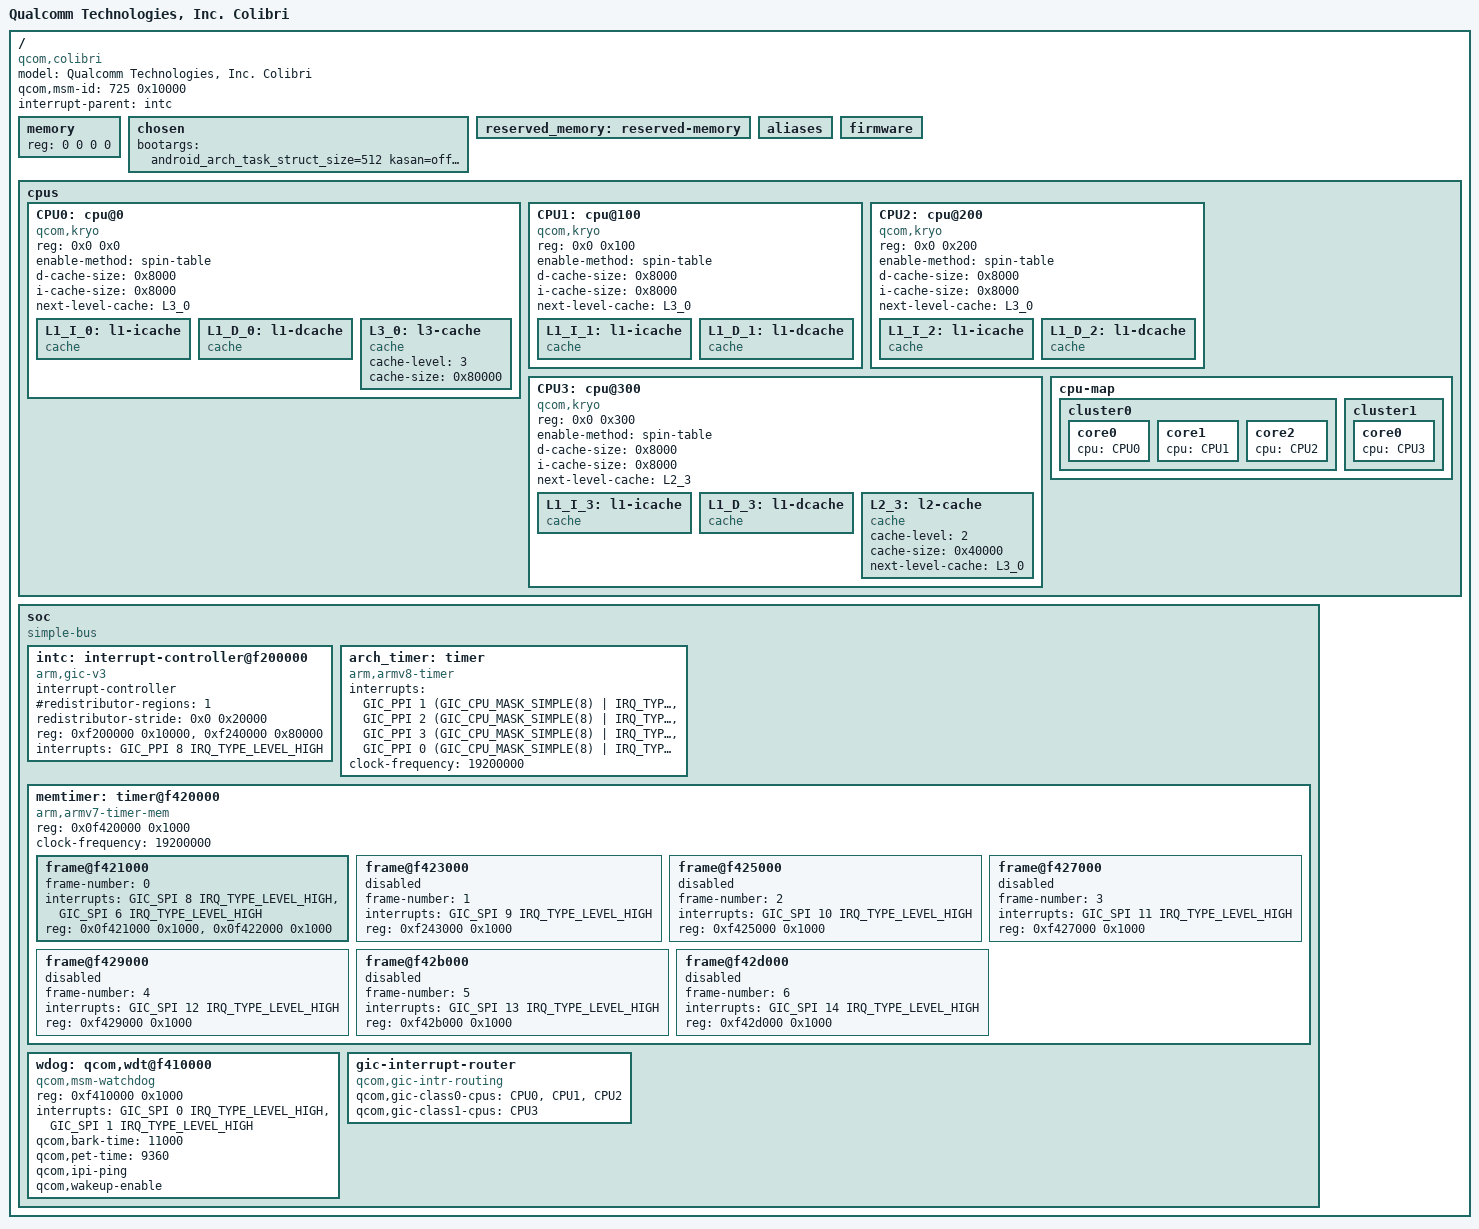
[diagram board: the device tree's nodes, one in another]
// SPDX-License-Identifier: BSD-3-Clause
/*
 * Copyright (c) Qualcomm Technologies, Inc. and/or its subsidiaries.
 */

#include <dt-bindings/interrupt-controller/arm-gic.h>
#include <dt-bindings/regulator/qcom,rpmh-regulator-levels.h>

/ {
	model = "Qualcomm Technologies, Inc. Colibri";
	compatible = "qcom,colibri";
	qcom,msm-id = <725 0x10000 >;//TODO - update actual msm-id for shikra
	interrupt-parent = <&intc>;
	#address-cells = <2>;
	#size-cells = <2>;
	memory { device_type = "memory"; reg = <0 0 0 0>; };

	chosen: chosen {
		bootargs = "android_arch_task_struct_size=512 kasan=off irqaffinity=0-1 cpufreq.default_governor=performance printk.console_no_auto_verbose=1 rcupdate.rcu_expedited=1 rcu_nocbs=0-4 nokaslr kpti=0 log_buf_len=256K swiotlb=0 loop.max_part=7 loglevel=8";
	};

	reserved_memory: reserved-memory { };

	aliases { };

	firmware: firmware {};

	cpus {
		#address-cells = <2>;
		#size-cells = <0>;

		CPU0: cpu@0 {
			device_type = "cpu";
			compatible = "qcom,kryo";
			reg = <0x0 0x0>;
			enable-method = "spin-table"; /* TODO: Update to psci */
			d-cache-size = <0x8000>;
			i-cache-size = <0x8000>;
			next-level-cache = <&L3_0>;

			L1_I_0: l1-icache {
				compatible = "cache";
			};

			L1_D_0: l1-dcache {
				compatible = "cache";
			};

			L3_0: l3-cache {
				compatible = "cache";
				cache-level = <3>;
				cache-size = <0x80000>;
			};
		};

		CPU1: cpu@100 {
			device_type = "cpu";
			compatible = "qcom,kryo";
			reg = <0x0 0x100>;
			enable-method = "spin-table"; /* TODO: Update to psci */
			d-cache-size = <0x8000>;
			i-cache-size = <0x8000>;
			next-level-cache = <&L3_0>;

			L1_I_1: l1-icache {
				compatible = "cache";
			};

			L1_D_1: l1-dcache {
				compatible = "cache";
			};
		};

		CPU2: cpu@200 {
			device_type = "cpu";
			compatible = "qcom,kryo";
			reg = <0x0 0x200>;
			enable-method = "spin-table"; /* TODO: Update to psci */
			d-cache-size = <0x8000>;
			i-cache-size = <0x8000>;
			next-level-cache = <&L3_0>;

			L1_I_2: l1-icache {
				compatible = "cache";
			};

			L1_D_2: l1-dcache {
				compatible = "cache";
			};
		};

		CPU3: cpu@300 {
			device_type = "cpu";
			compatible = "qcom,kryo";
			reg = <0x0 0x300>;
			enable-method = "spin-table"; /* TODO: Update to psci */
			d-cache-size = <0x8000>;
			i-cache-size = <0x8000>;
			next-level-cache = <&L2_3>;

			L1_I_3: l1-icache {
				compatible = "cache";
			};

			L1_D_3: l1-dcache {
				compatible = "cache";
			};

			L2_3: l2-cache {
				compatible = "cache";
				cache-level = <2>;
				cache-size = <0x40000>;
				next-level-cache = <&L3_0>;
			};
		};

		cpu-map {
			cluster0 {
				core0 {
					cpu = <&CPU0>;
				};

				core1 {
					cpu = <&CPU1>;
				};

				core2 {
					cpu = <&CPU2>;
				};
			};

			cluster1 {
				core0 {
					cpu = <&CPU3>;
				};
			};
		};
	};

	soc: soc { };

};

&soc {
	#address-cells = <1>;
	#size-cells = <1>;
	ranges = <0 0 0 0xffffffff>;
	compatible = "simple-bus";

	intc: interrupt-controller@f200000 {
		compatible = "arm,gic-v3";
		#interrupt-cells = <3>;
		interrupt-controller;
		#redistributor-regions = <1>;
		redistributor-stride = <0x0 0x20000>;
		reg = <0xf200000 0x10000>,	/* GICD */
		      <0xf240000 0x80000>;	/* GICR * 4 */
		interrupts = <GIC_PPI 8 IRQ_TYPE_LEVEL_HIGH>;
	};

	arch_timer: timer {
		compatible = "arm,armv8-timer";
		interrupts = <GIC_PPI 1 (GIC_CPU_MASK_SIMPLE(8) | IRQ_TYPE_LEVEL_LOW)>,
			     <GIC_PPI 2 (GIC_CPU_MASK_SIMPLE(8) | IRQ_TYPE_LEVEL_LOW)>,
			     <GIC_PPI 3 (GIC_CPU_MASK_SIMPLE(8) | IRQ_TYPE_LEVEL_LOW)>,
			     <GIC_PPI 0 (GIC_CPU_MASK_SIMPLE(8) | IRQ_TYPE_LEVEL_LOW)>;
		clock-frequency = <19200000>;
	};

	memtimer: timer@f420000 {
		#address-cells = <1>;
		#size-cells = <1>;
		ranges;
		compatible = "arm,armv7-timer-mem";
		reg = <0x0f420000 0x1000>;
		clock-frequency = <19200000>;

		frame@f421000 {
			frame-number = <0>;
			interrupts = <GIC_SPI 8 IRQ_TYPE_LEVEL_HIGH>,
				     <GIC_SPI 6 IRQ_TYPE_LEVEL_HIGH>;
			reg = <0x0f421000 0x1000>,
			      <0x0f422000 0x1000>;
		};

		frame@f423000 {
			frame-number = <1>;
			interrupts = <GIC_SPI 9 IRQ_TYPE_LEVEL_HIGH>;
			reg = <0xf243000 0x1000>;
			status = "disabled";
		};

		frame@f425000 {
			frame-number = <2>;
			interrupts = <GIC_SPI 10 IRQ_TYPE_LEVEL_HIGH>;
			reg = <0xf425000 0x1000>;
			status = "disabled";
		};

		frame@f427000 {
			frame-number = <3>;
			interrupts = <GIC_SPI 11 IRQ_TYPE_LEVEL_HIGH>;
			reg = <0xf427000 0x1000>;
			status = "disabled";
		};

		frame@f429000 {
			frame-number = <4>;
			interrupts = <GIC_SPI 12 IRQ_TYPE_LEVEL_HIGH>;
			reg = <0xf429000 0x1000>;
			status = "disabled";
		};

		frame@f42b000 {
			frame-number = <5>;
			interrupts = <GIC_SPI 13 IRQ_TYPE_LEVEL_HIGH>;
			reg = <0xf42b000 0x1000>;
			status = "disabled";
		};

		frame@f42d000 {
			frame-number = <6>;
			interrupts = <GIC_SPI 14 IRQ_TYPE_LEVEL_HIGH>;
			reg = <0xf42d000 0x1000>;
			status = "disabled";
		};
	};

	wdog: qcom,wdt@f410000 {
		compatible = "qcom,msm-watchdog";
		reg = <0xf410000 0x1000>;
		reg-names = "wdt-base";
		interrupts = <GIC_SPI 0 IRQ_TYPE_LEVEL_HIGH>,
			     <GIC_SPI 1 IRQ_TYPE_LEVEL_HIGH>;
		qcom,bark-time = <11000>;
		qcom,pet-time = <9360>;
		qcom,ipi-ping;
		qcom,wakeup-enable;
		status = "ok";
	};

	gic-interrupt-router {
		compatible = "qcom,gic-intr-routing";
		/* keep a few m cores in class0 only to avoid wakeup of l cores */
		qcom,gic-class0-cpus = <&CPU0 &CPU1 &CPU2>;
		/* keep other cores in class1 */
		qcom,gic-class1-cpus = <&CPU3>;
	};
};

#include "colibri-pinctrl.dtsi"
#include "colibri-reserved-memory.dtsi"
#include "colibri-stub-regulators.dtsi"
#include "msm-arm-smmu-colibri.dtsi"
#include "colibri-dma-heaps.dtsi"
